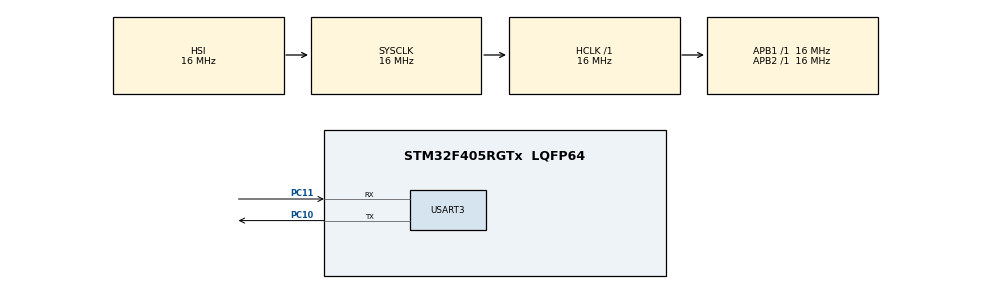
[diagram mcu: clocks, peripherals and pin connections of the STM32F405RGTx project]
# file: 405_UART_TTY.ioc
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Mcu.Family=STM32F4
Mcu.Name=STM32F405RGTx
Mcu.Package=LQFP64
NVIC.PriorityGroup=NVIC_PRIORITYGROUP_4
PA13.Mode=Serial_Wire
PA13.Signal=SYS_JTMS-SWDIO
PA14.Mode=Serial_Wire
PA14.Signal=SYS_JTCK-SWCLK
PC10.Mode=Asynchronous
PC10.Signal=USART3_TX
PC11.Mode=Asynchronous
PC11.Signal=USART3_RX
PC14-OSC32_IN.Mode=LSE-External-Oscillator
PC14-OSC32_IN.Signal=RCC_OSC32_IN
PC15-OSC32_OUT.Mode=LSE-External-Oscillator
PC15-OSC32_OUT.Signal=RCC_OSC32_OUT
PH0-OSC_IN.Mode=HSE-External-Oscillator
PH0-OSC_IN.Signal=RCC_OSC_IN
PH1-OSC_OUT.Mode=HSE-External-Oscillator
PH1-OSC_OUT.Signal=RCC_OSC_OUT
ProjectManager.HeapSize=0x200
ProjectManager.StackSize=0x400
ProjectManager.TargetToolchain=STM32CubeIDE
RCC.AHBFreq_Value=16000000
RCC.APB1Freq_Value=16000000
RCC.APB2Freq_Value=16000000
RCC.CortexFreq_Value=16000000
RCC.HSE_VALUE=25000000
RCC.HSI_VALUE=16000000
RCC.SYSCLKFreq_VALUE=16000000
RCC.VCOOutputFreq_Value=192000000
USART3.VirtualMode=VM_ASYNC
board=custom

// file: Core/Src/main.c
/* USER CODE BEGIN Header */
/**
  ******************************************************************************
  * @file           : main.c
  * @brief          : Main program body
  ******************************************************************************
  * @attention
  *
  * Copyright (c) 2025 STMicroelectronics.
  * All rights reserved.
  *
  * This software is licensed under terms that can be found in the LICENSE file
  * in the root directory of this software component.
  * If no LICENSE file comes with this software, it is provided AS-IS.
  *
  ******************************************************************************
  */
/* USER CODE END Header */
#include "main.h"

UART_HandleTypeDef huart3;

void SystemClock_Config(void);
static void MX_GPIO_Init(void);
static void MX_USART3_UART_Init(void);

int main(void)
{

  /* USER CODE BEGIN 1 */
	uint8_t data[20]="HELLO WORLD!";
  /* USER CODE END 1 */

  /* MCU Configuration--------------------------------------------------------*/

  /* Reset of all peripherals, Initializes the Flash interface and the Systick. */
  HAL_Init();

  /* Configure the system clock */
  SystemClock_Config();

  /* Initialize all configured peripherals */
  MX_GPIO_Init();
  MX_USART3_UART_Init();

  /* Infinite loop */
  while (1)
  {
	  HAL_UART_Transmit(&huart3, data, sizeof(data), HAL_MAX_DELAY);
	  HAL_Delay(1000);
  }
}

void SystemClock_Config(void)
{
  RCC_OscInitTypeDef RCC_OscInitStruct = {0};
  RCC_ClkInitTypeDef RCC_ClkInitStruct = {0};

  /** Configure the main internal regulator output voltage
  */
  __HAL_RCC_PWR_CLK_ENABLE();
  __HAL_PWR_VOLTAGESCALING_CONFIG(PWR_REGULATOR_VOLTAGE_SCALE1);

  /** Initializes the RCC Oscillators according to the specified parameters
  * in the RCC_OscInitTypeDef structure.
  */
  RCC_OscInitStruct.OscillatorType = RCC_OSCILLATORTYPE_HSI;
  RCC_OscInitStruct.HSIState = RCC_HSI_ON;
  RCC_OscInitStruct.HSICalibrationValue = RCC_HSICALIBRATION_DEFAULT;
  RCC_OscInitStruct.PLL.PLLState = RCC_PLL_NONE;
  if (HAL_RCC_OscConfig(&RCC_OscInitStruct) != HAL_OK)
  {
    Error_Handler();
  }

  /** Initializes the CPU, AHB and APB buses clocks
  */
  RCC_ClkInitStruct.ClockType = RCC_CLOCKTYPE_HCLK|RCC_CLOCKTYPE_SYSCLK
                              |RCC_CLOCKTYPE_PCLK1|RCC_CLOCKTYPE_PCLK2;
  RCC_ClkInitStruct.SYSCLKSource = RCC_SYSCLKSOURCE_HSI;
  RCC_ClkInitStruct.AHBCLKDivider = RCC_SYSCLK_DIV1;
  RCC_ClkInitStruct.APB1CLKDivider = RCC_HCLK_DIV1;
  RCC_ClkInitStruct.APB2CLKDivider = RCC_HCLK_DIV1;

  if (HAL_RCC_ClockConfig(&RCC_ClkInitStruct, FLASH_LATENCY_0) != HAL_OK)
  {
    Error_Handler();
  }
}

static void MX_USART3_UART_Init(void)
{

  huart3.Instance = USART3;
  huart3.Init.BaudRate = 115200;
  huart3.Init.WordLength = UART_WORDLENGTH_8B;
  huart3.Init.StopBits = UART_STOPBITS_1;
  huart3.Init.Parity = UART_PARITY_NONE;
  huart3.Init.Mode = UART_MODE_TX_RX;
  huart3.Init.HwFlowCtl = UART_HWCONTROL_NONE;
  huart3.Init.OverSampling = UART_OVERSAMPLING_16;
  if (HAL_UART_Init(&huart3) != HAL_OK)
  {
    Error_Handler();
  }

}

static void MX_GPIO_Init(void)
{

  /* GPIO Ports Clock Enable */
  __HAL_RCC_GPIOC_CLK_ENABLE();
  __HAL_RCC_GPIOH_CLK_ENABLE();
  __HAL_RCC_GPIOA_CLK_ENABLE();

}

void Error_Handler(void)
{
  __disable_irq();
  while (1)
  {
  }
}
